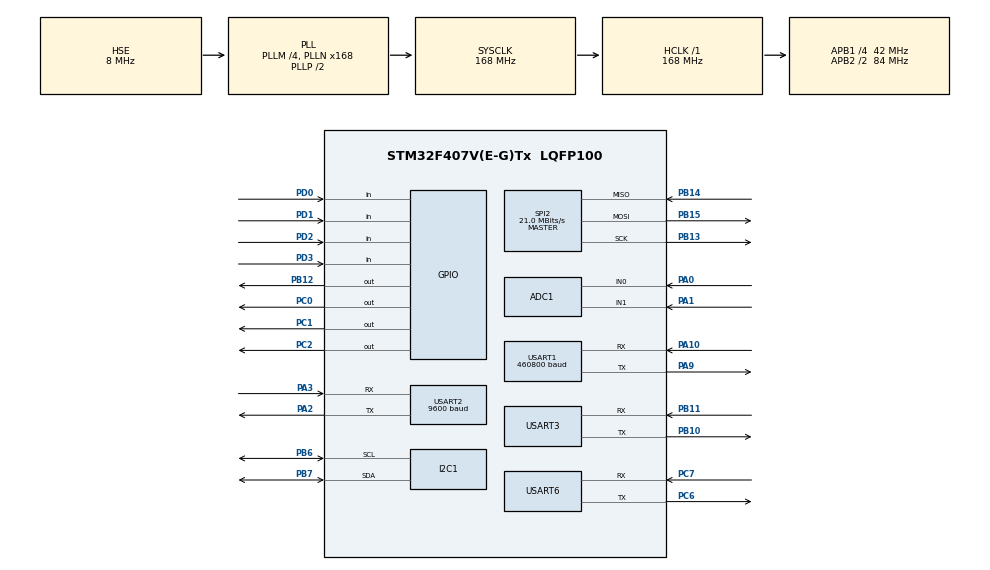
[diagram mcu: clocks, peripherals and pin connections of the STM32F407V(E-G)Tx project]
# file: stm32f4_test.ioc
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ADC1.Channel-0\#ChannelRegularConversion=ADC_CHANNEL_0
ADC1.Channel-1\#ChannelRegularConversion=ADC_CHANNEL_1
ADC1.ContinuousConvMode=ENABLE
ADC1.DMAContinuousRequests=ENABLE
ADC1.NbrOfConversion=2
ADC1.NbrOfConversionFlag=1
ADC1.Rank-0\#ChannelRegularConversion=1
ADC1.Rank-1\#ChannelRegularConversion=2
ADC1.SamplingTime-0\#ChannelRegularConversion=ADC_SAMPLETIME_15CYCLES
ADC1.SamplingTime-1\#ChannelRegularConversion=ADC_SAMPLETIME_144CYCLES
ADC1.ScanConvMode=ENABLE
ADC1.master=1
Dma.ADC1.3.Direction=DMA_PERIPH_TO_MEMORY
Dma.ADC1.3.FIFOMode=DMA_FIFOMODE_DISABLE
Dma.ADC1.3.Instance=DMA2_Stream0
Dma.ADC1.3.MemDataAlignment=DMA_MDATAALIGN_WORD
Dma.ADC1.3.MemInc=DMA_MINC_ENABLE
Dma.ADC1.3.Mode=DMA_CIRCULAR
Dma.ADC1.3.PeriphDataAlignment=DMA_PDATAALIGN_WORD
Dma.ADC1.3.PeriphInc=DMA_PINC_DISABLE
Dma.ADC1.3.Priority=DMA_PRIORITY_LOW
Dma.Request0=USART1_RX
Dma.Request1=USART2_RX
Dma.Request2=USART3_RX
Dma.Request3=ADC1
Dma.Request4=USART6_RX
Dma.USART1_RX.0.Direction=DMA_PERIPH_TO_MEMORY
Dma.USART1_RX.0.FIFOMode=DMA_FIFOMODE_DISABLE
Dma.USART1_RX.0.Instance=DMA2_Stream2
Dma.USART1_RX.0.MemDataAlignment=DMA_MDATAALIGN_BYTE
Dma.USART1_RX.0.MemInc=DMA_MINC_ENABLE
Dma.USART1_RX.0.Mode=DMA_NORMAL
Dma.USART1_RX.0.PeriphDataAlignment=DMA_PDATAALIGN_BYTE
Dma.USART1_RX.0.PeriphInc=DMA_PINC_DISABLE
Dma.USART1_RX.0.Priority=DMA_PRIORITY_LOW
Dma.USART2_RX.1.Direction=DMA_PERIPH_TO_MEMORY
Dma.USART2_RX.1.FIFOMode=DMA_FIFOMODE_DISABLE
Dma.USART2_RX.1.Instance=DMA1_Stream5
Dma.USART2_RX.1.MemDataAlignment=DMA_MDATAALIGN_BYTE
Dma.USART2_RX.1.MemInc=DMA_MINC_ENABLE
Dma.USART2_RX.1.Mode=DMA_NORMAL
Dma.USART2_RX.1.PeriphDataAlignment=DMA_PDATAALIGN_BYTE
Dma.USART2_RX.1.PeriphInc=DMA_PINC_DISABLE
Dma.USART2_RX.1.Priority=DMA_PRIORITY_LOW
Dma.USART3_RX.2.Direction=DMA_PERIPH_TO_MEMORY
Dma.USART3_RX.2.FIFOMode=DMA_FIFOMODE_DISABLE
Dma.USART3_RX.2.Instance=DMA1_Stream1
Dma.USART3_RX.2.MemDataAlignment=DMA_MDATAALIGN_BYTE
Dma.USART3_RX.2.MemInc=DMA_MINC_ENABLE
Dma.USART3_RX.2.Mode=DMA_NORMAL
Dma.USART3_RX.2.PeriphDataAlignment=DMA_PDATAALIGN_BYTE
Dma.USART3_RX.2.PeriphInc=DMA_PINC_DISABLE
Dma.USART3_RX.2.Priority=DMA_PRIORITY_LOW
Dma.USART6_RX.4.Direction=DMA_PERIPH_TO_MEMORY
Dma.USART6_RX.4.FIFOMode=DMA_FIFOMODE_DISABLE
Dma.USART6_RX.4.Instance=DMA2_Stream1
Dma.USART6_RX.4.MemDataAlignment=DMA_MDATAALIGN_BYTE
Dma.USART6_RX.4.MemInc=DMA_MINC_ENABLE
Dma.USART6_RX.4.Mode=DMA_NORMAL
Dma.USART6_RX.4.PeriphDataAlignment=DMA_PDATAALIGN_BYTE
Dma.USART6_RX.4.PeriphInc=DMA_PINC_DISABLE
Dma.USART6_RX.4.Priority=DMA_PRIORITY_LOW
I2C1.I2C_Mode=I2C_Fast
Mcu.Family=STM32F4
Mcu.Name=STM32F407V(E-G)Tx
Mcu.Package=LQFP100
NVIC.DMA1_Stream1_IRQn=true\:0\:0\:false\:false\:true\:false\:true\:true
NVIC.DMA1_Stream5_IRQn=true\:0\:0\:false\:false\:true\:false\:true\:true
NVIC.DMA2_Stream0_IRQn=true\:0\:0\:false\:false\:true\:false\:true\:true
NVIC.DMA2_Stream1_IRQn=true\:0\:0\:false\:false\:true\:false\:true\:true
NVIC.DMA2_Stream2_IRQn=true\:0\:0\:false\:false\:true\:false\:true\:true
NVIC.PriorityGroup=NVIC_PRIORITYGROUP_4
NVIC.USART1_IRQn=true\:0\:0\:false\:false\:true\:true\:true\:true
NVIC.USART2_IRQn=true\:0\:0\:false\:false\:true\:true\:true\:true
NVIC.USART3_IRQn=true\:0\:0\:false\:false\:true\:true\:true\:true
NVIC.USART6_IRQn=true\:0\:0\:false\:false\:true\:true\:true\:true
PA0-WKUP.Signal=ADCx_IN0
PA1.Signal=ADCx_IN1
PA10.Mode=Asynchronous
PA10.Signal=USART1_RX
PA13.Mode=Serial_Wire
PA13.Signal=SYS_JTMS-SWDIO
PA14.Mode=Serial_Wire
PA14.Signal=SYS_JTCK-SWCLK
PA2.Mode=Asynchronous
PA2.Signal=USART2_TX
PA3.Mode=Asynchronous
PA3.Signal=USART2_RX
PA9.Mode=Asynchronous
PA9.Signal=USART1_TX
PB10.Mode=Asynchronous
PB10.Signal=USART3_TX
PB11.Mode=Asynchronous
PB11.Signal=USART3_RX
PB12.Signal=GPIO_Output
PB13.Mode=Full_Duplex_Master
PB13.Signal=SPI2_SCK
PB14.Mode=Full_Duplex_Master
PB14.Signal=SPI2_MISO
PB15.Mode=Full_Duplex_Master
PB15.Signal=SPI2_MOSI
PB6.Mode=I2C
PB6.Signal=I2C1_SCL
PB7.Mode=I2C
PB7.Signal=I2C1_SDA
PC0.GPIO_ModeDefaultOutputPP=GPIO_MODE_OUTPUT_PP
PC0.GPIO_PuPd=GPIO_NOPULL
PC0.GPIO_Speed=GPIO_SPEED_FREQ_HIGH
PC0.PinState=GPIO_PIN_RESET
PC0.Signal=GPIO_Output
PC1.GPIO_ModeDefaultOutputPP=GPIO_MODE_OUTPUT_PP
PC1.GPIO_PuPd=GPIO_NOPULL
PC1.GPIO_Speed=GPIO_SPEED_FREQ_HIGH
PC1.PinState=GPIO_PIN_RESET
PC1.Signal=GPIO_Output
PC14-OSC32_IN.Mode=LSE-External-Oscillator
PC14-OSC32_IN.Signal=RCC_OSC32_IN
PC15-OSC32_OUT.Mode=LSE-External-Oscillator
PC15-OSC32_OUT.Signal=RCC_OSC32_OUT
PC2.GPIO_ModeDefaultOutputPP=GPIO_MODE_OUTPUT_PP
PC2.GPIO_PuPd=GPIO_NOPULL
PC2.GPIO_Speed=GPIO_SPEED_FREQ_HIGH
PC2.PinState=GPIO_PIN_RESET
PC2.Signal=GPIO_Output
PC6.Mode=Asynchronous
PC6.Signal=USART6_TX
PC7.Mode=Asynchronous
PC7.Signal=USART6_RX
PD0.GPIO_PuPd=GPIO_PULLUP
PD0.Signal=GPIO_Input
PD1.GPIO_PuPd=GPIO_PULLUP
PD1.Signal=GPIO_Input
PD2.GPIO_PuPd=GPIO_PULLUP
PD2.Signal=GPIO_Input
PD3.GPIO_PuPd=GPIO_PULLUP
PD3.Signal=GPIO_Input
PH0-OSC_IN.Mode=HSE-External-Oscillator
PH0-OSC_IN.Signal=RCC_OSC_IN
PH1-OSC_OUT.Mode=HSE-External-Oscillator
PH1-OSC_OUT.Signal=RCC_OSC_OUT
ProjectManager.HeapSize=0x200
ProjectManager.StackSize=0x400
ProjectManager.TargetToolchain=MDK-ARM V5.32
RCC.48MHZClocksFreq_Value=84000000
RCC.AHBFreq_Value=168000000
RCC.APB1CLKDivider=RCC_HCLK_DIV4
RCC.APB1Freq_Value=42000000
RCC.APB1TimFreq_Value=84000000
RCC.APB2CLKDivider=RCC_HCLK_DIV2
RCC.APB2Freq_Value=84000000
RCC.APB2TimFreq_Value=168000000
RCC.CortexFreq_Value=168000000
RCC.HCLKFreq_Value=168000000
RCC.HSE_VALUE=8000000
RCC.HSI_VALUE=16000000
RCC.PLLM=4
RCC.PLLN=168
RCC.PLLSourceVirtual=RCC_PLLSOURCE_HSE
RCC.SYSCLKFreq_VALUE=168000000
RCC.SYSCLKSource=RCC_SYSCLKSOURCE_PLLCLK
RCC.VCOOutputFreq_Value=336000000
RTC.Hours=1
RTC.Seconds=50
SH.ADCx_IN0.0=ADC1_IN0,IN0
SH.ADCx_IN1.0=ADC1_IN1,IN1
SPI2.CalculateBaudRate=21.0 MBits/s
SPI2.Direction=SPI_DIRECTION_2LINES
SPI2.Mode=SPI_MODE_MASTER
SPI2.VirtualType=VM_MASTER
USART1.BaudRate=460800
USART1.VirtualMode=VM_ASYNC
USART2.BaudRate=9600
USART2.VirtualMode=VM_ASYNC
USART3.VirtualMode=VM_ASYNC
USART6.VirtualMode=VM_ASYNC
VP_RTC_VS_RTC_Activate.Mode=RTC_Enabled
VP_RTC_VS_RTC_Calendar.Mode=RTC_Calendar
board=custom

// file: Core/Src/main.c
/* USER CODE BEGIN Header */
/**
  ******************************************************************************
  * @file           : main.c
  * @brief          : Main program body
  ******************************************************************************
  * @attention
  *
  * Copyright (c) 2025 STMicroelectronics.
  * All rights reserved.
  *
  * This software is licensed under terms that can be found in the LICENSE file
  * in the root directory of this software component.
  * If no LICENSE file comes with this software, it is provided AS-IS.
  *
  ******************************************************************************
  */
/* USER CODE END Header */
#include "main.h"
#include "adc.h"
#include "dma.h"
#include "i2c.h"
#include "rtc.h"
#include "spi.h"
#include "usart.h"
#include "gpio.h"

/* USER CODE BEGIN Includes */
#include "define.h"
/* USER CODE END Includes */

void SystemClock_Config(void);

int main(void)
{

  /* MCU Configuration--------------------------------------------------------*/

  /* Reset of all peripherals, Initializes the Flash interface and the Systick. */
  HAL_Init();

  /* Configure the system clock */
  SystemClock_Config();

  /* Initialize all configured peripherals */
  MX_GPIO_Init();
  MX_DMA_Init();
  MX_USART1_UART_Init();
  MX_USART2_UART_Init();
  MX_USART3_UART_Init();
  MX_I2C1_Init();
  MX_ADC1_Init();
  MX_USART6_UART_Init();
  MX_RTC_Init();
  MX_SPI2_Init();
  /* USER CODE BEGIN 2 */
	scheduler_init();
	buffer_init();
	OLED_Init();
	adc_dma_init();
	MD25Q64_Test_RunAll();
  /* USER CODE END 2 */

  /* Infinite loop */
  /* USER CODE BEGIN WHILE */
  while (1)
  {
		scheduler_run();
    /* USER CODE END WHILE */

  }
}

void SystemClock_Config(void)
{
  RCC_OscInitTypeDef RCC_OscInitStruct = {0};
  RCC_ClkInitTypeDef RCC_ClkInitStruct = {0};

  /** Configure the main internal regulator output voltage
  */
  __HAL_RCC_PWR_CLK_ENABLE();
  __HAL_PWR_VOLTAGESCALING_CONFIG(PWR_REGULATOR_VOLTAGE_SCALE1);

  /** Initializes the RCC Oscillators according to the specified parameters
  * in the RCC_OscInitTypeDef structure.
  */
  RCC_OscInitStruct.OscillatorType = RCC_OSCILLATORTYPE_LSI|RCC_OSCILLATORTYPE_HSE;
  RCC_OscInitStruct.HSEState = RCC_HSE_ON;
  RCC_OscInitStruct.LSIState = RCC_LSI_ON;
  RCC_OscInitStruct.PLL.PLLState = RCC_PLL_ON;
  RCC_OscInitStruct.PLL.PLLSource = RCC_PLLSOURCE_HSE;
  RCC_OscInitStruct.PLL.PLLM = 4;
  RCC_OscInitStruct.PLL.PLLN = 168;
  RCC_OscInitStruct.PLL.PLLP = RCC_PLLP_DIV2;
  RCC_OscInitStruct.PLL.PLLQ = 4;
  if (HAL_RCC_OscConfig(&RCC_OscInitStruct) != HAL_OK)
  {
    Error_Handler();
  }

  /** Initializes the CPU, AHB and APB buses clocks
  */
  RCC_ClkInitStruct.ClockType = RCC_CLOCKTYPE_HCLK|RCC_CLOCKTYPE_SYSCLK
                              |RCC_CLOCKTYPE_PCLK1|RCC_CLOCKTYPE_PCLK2;
  RCC_ClkInitStruct.SYSCLKSource = RCC_SYSCLKSOURCE_PLLCLK;
  RCC_ClkInitStruct.AHBCLKDivider = RCC_SYSCLK_DIV1;
  RCC_ClkInitStruct.APB1CLKDivider = RCC_HCLK_DIV4;
  RCC_ClkInitStruct.APB2CLKDivider = RCC_HCLK_DIV2;

  if (HAL_RCC_ClockConfig(&RCC_ClkInitStruct, FLASH_LATENCY_5) != HAL_OK)
  {
    Error_Handler();
  }
}

void Error_Handler(void)
{
  __disable_irq();
  while (1)
  {
  }
}
